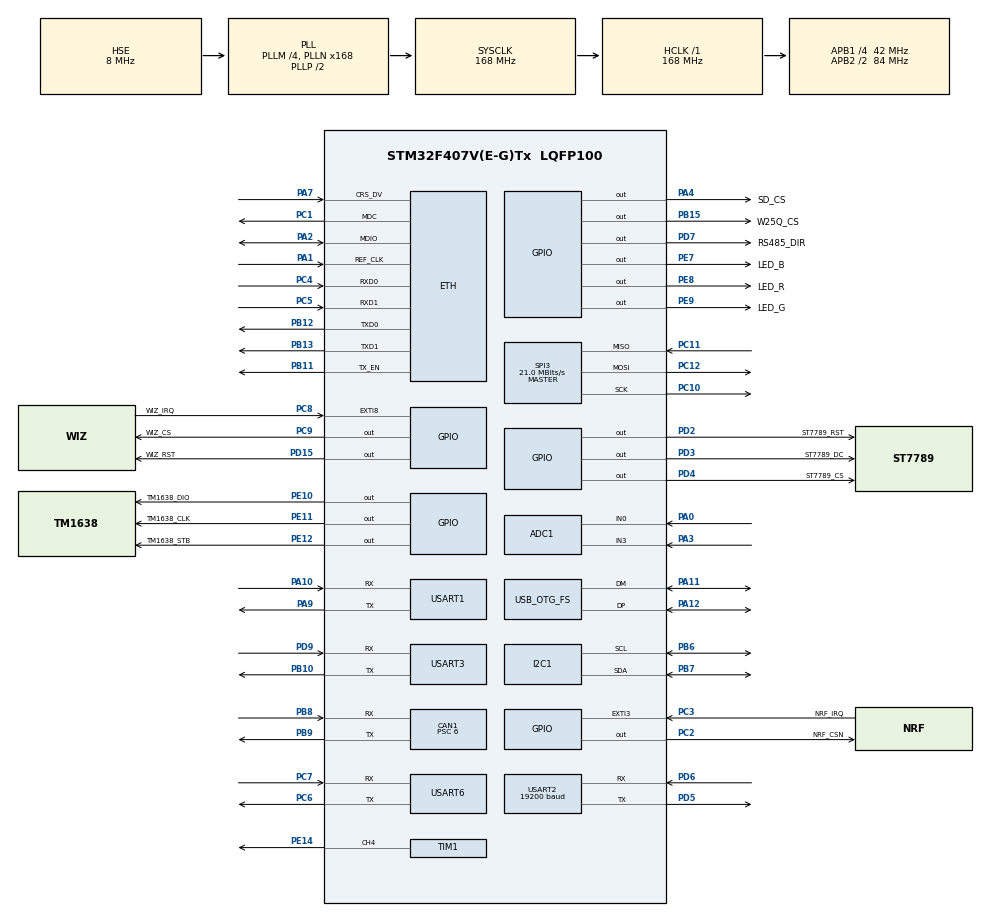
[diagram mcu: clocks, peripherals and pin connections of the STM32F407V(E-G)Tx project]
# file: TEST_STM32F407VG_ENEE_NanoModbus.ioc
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ADC1.Channel-0\#ChannelRegularConversion=ADC_CHANNEL_0
ADC1.NbrOfConversionFlag=1
ADC1.Rank-0\#ChannelRegularConversion=1
ADC1.SamplingTime-0\#ChannelRegularConversion=ADC_SAMPLETIME_3CYCLES
ADC1.master=1
CAN1.BS1=CAN_BS1_11TQ
CAN1.BS2=CAN_BS2_2TQ
CAN1.CalculateBaudRate=500000
CAN1.CalculateTimeBit=2000
CAN1.CalculateTimeQuantum=142.85714285714286
CAN1.Prescaler=6
Dma.Request0=USART1_RX
Dma.Request1=USART1_TX
Dma.Request2=SPI3_TX
Dma.Request3=TIM1_CH4/TRIG/COM
Dma.Request4=USART3_RX
Dma.Request5=USART3_TX
Dma.Request6=USART2_RX
Dma.Request7=USART2_TX
Dma.SPI3_TX.2.Direction=DMA_MEMORY_TO_PERIPH
Dma.SPI3_TX.2.FIFOMode=DMA_FIFOMODE_DISABLE
Dma.SPI3_TX.2.Instance=DMA1_Stream7
Dma.SPI3_TX.2.MemDataAlignment=DMA_MDATAALIGN_BYTE
Dma.SPI3_TX.2.MemInc=DMA_MINC_ENABLE
Dma.SPI3_TX.2.Mode=DMA_NORMAL
Dma.SPI3_TX.2.PeriphDataAlignment=DMA_PDATAALIGN_BYTE
Dma.SPI3_TX.2.PeriphInc=DMA_PINC_DISABLE
Dma.SPI3_TX.2.Priority=DMA_PRIORITY_LOW
Dma.TIM1_CH4/TRIG/COM.3.Direction=DMA_MEMORY_TO_PERIPH
Dma.TIM1_CH4/TRIG/COM.3.FIFOMode=DMA_FIFOMODE_DISABLE
Dma.TIM1_CH4/TRIG/COM.3.Instance=DMA2_Stream4
Dma.TIM1_CH4/TRIG/COM.3.MemDataAlignment=DMA_MDATAALIGN_HALFWORD
Dma.TIM1_CH4/TRIG/COM.3.MemInc=DMA_MINC_ENABLE
Dma.TIM1_CH4/TRIG/COM.3.Mode=DMA_NORMAL
Dma.TIM1_CH4/TRIG/COM.3.PeriphDataAlignment=DMA_PDATAALIGN_HALFWORD
Dma.TIM1_CH4/TRIG/COM.3.PeriphInc=DMA_PINC_DISABLE
Dma.TIM1_CH4/TRIG/COM.3.Priority=DMA_PRIORITY_MEDIUM
Dma.USART1_RX.0.Direction=DMA_PERIPH_TO_MEMORY
Dma.USART1_RX.0.FIFOMode=DMA_FIFOMODE_DISABLE
Dma.USART1_RX.0.Instance=DMA2_Stream2
Dma.USART1_RX.0.MemDataAlignment=DMA_MDATAALIGN_BYTE
Dma.USART1_RX.0.MemInc=DMA_MINC_ENABLE
Dma.USART1_RX.0.Mode=DMA_NORMAL
Dma.USART1_RX.0.PeriphDataAlignment=DMA_PDATAALIGN_BYTE
Dma.USART1_RX.0.PeriphInc=DMA_PINC_DISABLE
Dma.USART1_RX.0.Priority=DMA_PRIORITY_LOW
Dma.USART1_TX.1.Direction=DMA_MEMORY_TO_PERIPH
Dma.USART1_TX.1.FIFOMode=DMA_FIFOMODE_DISABLE
Dma.USART1_TX.1.Instance=DMA2_Stream7
Dma.USART1_TX.1.MemDataAlignment=DMA_MDATAALIGN_BYTE
Dma.USART1_TX.1.MemInc=DMA_MINC_ENABLE
Dma.USART1_TX.1.Mode=DMA_NORMAL
Dma.USART1_TX.1.PeriphDataAlignment=DMA_PDATAALIGN_BYTE
Dma.USART1_TX.1.PeriphInc=DMA_PINC_DISABLE
Dma.USART1_TX.1.Priority=DMA_PRIORITY_LOW
Dma.USART2_RX.6.Direction=DMA_PERIPH_TO_MEMORY
Dma.USART2_RX.6.FIFOMode=DMA_FIFOMODE_DISABLE
Dma.USART2_RX.6.Instance=DMA1_Stream5
Dma.USART2_RX.6.MemDataAlignment=DMA_MDATAALIGN_BYTE
Dma.USART2_RX.6.MemInc=DMA_MINC_ENABLE
Dma.USART2_RX.6.Mode=DMA_CIRCULAR
Dma.USART2_RX.6.PeriphDataAlignment=DMA_PDATAALIGN_BYTE
Dma.USART2_RX.6.PeriphInc=DMA_PINC_DISABLE
Dma.USART2_RX.6.Priority=DMA_PRIORITY_LOW
Dma.USART2_TX.7.Direction=DMA_MEMORY_TO_PERIPH
Dma.USART2_TX.7.FIFOMode=DMA_FIFOMODE_DISABLE
Dma.USART2_TX.7.Instance=DMA1_Stream6
Dma.USART2_TX.7.MemDataAlignment=DMA_MDATAALIGN_BYTE
Dma.USART2_TX.7.MemInc=DMA_MINC_ENABLE
Dma.USART2_TX.7.Mode=DMA_NORMAL
Dma.USART2_TX.7.PeriphDataAlignment=DMA_PDATAALIGN_BYTE
Dma.USART2_TX.7.PeriphInc=DMA_PINC_DISABLE
Dma.USART2_TX.7.Priority=DMA_PRIORITY_LOW
Dma.USART3_RX.4.Direction=DMA_PERIPH_TO_MEMORY
Dma.USART3_RX.4.FIFOMode=DMA_FIFOMODE_DISABLE
Dma.USART3_RX.4.Instance=DMA1_Stream1
Dma.USART3_RX.4.MemDataAlignment=DMA_MDATAALIGN_BYTE
Dma.USART3_RX.4.MemInc=DMA_MINC_ENABLE
Dma.USART3_RX.4.Mode=DMA_CIRCULAR
Dma.USART3_RX.4.PeriphDataAlignment=DMA_PDATAALIGN_BYTE
Dma.USART3_RX.4.PeriphInc=DMA_PINC_DISABLE
Dma.USART3_RX.4.Priority=DMA_PRIORITY_LOW
Dma.USART3_TX.5.Direction=DMA_MEMORY_TO_PERIPH
Dma.USART3_TX.5.FIFOMode=DMA_FIFOMODE_DISABLE
Dma.USART3_TX.5.Instance=DMA1_Stream3
Dma.USART3_TX.5.MemDataAlignment=DMA_MDATAALIGN_BYTE
Dma.USART3_TX.5.MemInc=DMA_MINC_ENABLE
Dma.USART3_TX.5.Mode=DMA_NORMAL
Dma.USART3_TX.5.PeriphDataAlignment=DMA_PDATAALIGN_BYTE
Dma.USART3_TX.5.PeriphInc=DMA_PINC_DISABLE
Dma.USART3_TX.5.Priority=DMA_PRIORITY_LOW
ETH.MediaInterface=HAL_ETH_RMII_MODE
FREERTOS.Tasks01=defaultTask,0,128,StartDefaultTask,Default,NULL,Dynamic,NULL,NULL
FREERTOS.configCHECK_FOR_STACK_OVERFLOW=2
FREERTOS.configTOTAL_HEAP_SIZE=25360
FREERTOS.configUSE_MALLOC_FAILED_HOOK=1
FREERTOS.configUSE_TIMERS=1
LWIP.BSP.number=1
LWIP.GATEWAY_ADDRESS=192.168.010.001
LWIP.IP_ADDRESS=192.168.010.010
LWIP.LWIP_DHCP=0
LWIP.NETMASK_ADDRESS=255.255.255.000
LWIP.Version=v2.1.2_Cube
LWIP0.BSP.STBoard=false
LWIP0.BSP.api=BSP_COMPONENT_DRIVER
LWIP0.BSP.component=LAN8742
LWIP0.BSP.instance=LAN8742
LWIP0.BSP.name=Driver_PHY
LWIP0.BSP.semaphore=S_LAN8742
LWIP0.BSP.solution=LAN8742
Mcu.Family=STM32F4
Mcu.Name=STM32F407V(E-G)Tx
Mcu.Package=LQFP100
NVIC.CAN1_RX0_IRQn=true\:5\:0\:false\:false\:true\:true\:true\:true\:true
NVIC.CAN1_RX1_IRQn=true\:5\:0\:false\:false\:true\:true\:true\:true\:true
NVIC.CAN1_SCE_IRQn=true\:5\:0\:false\:false\:true\:true\:true\:true\:true
NVIC.CAN1_TX_IRQn=true\:5\:0\:false\:false\:true\:true\:true\:true\:true
NVIC.DMA1_Stream1_IRQn=true\:5\:0\:false\:false\:true\:true\:false\:true\:true
NVIC.DMA1_Stream3_IRQn=true\:5\:0\:false\:false\:true\:true\:false\:true\:true
NVIC.DMA1_Stream5_IRQn=true\:5\:0\:false\:false\:true\:true\:false\:true\:true
NVIC.DMA1_Stream6_IRQn=true\:5\:0\:false\:false\:true\:true\:false\:true\:true
NVIC.DMA1_Stream7_IRQn=true\:5\:0\:false\:false\:true\:false\:false\:true\:true
NVIC.DMA2_Stream2_IRQn=true\:5\:0\:false\:false\:true\:true\:false\:true\:true
NVIC.DMA2_Stream4_IRQn=true\:5\:0\:false\:false\:true\:true\:false\:true\:true
NVIC.DMA2_Stream7_IRQn=true\:5\:0\:false\:false\:true\:true\:false\:true\:true
NVIC.ETH_IRQn=true\:5\:0\:false\:false\:true\:true\:false\:true\:true
NVIC.ETH_WKUP_IRQn=true\:5\:0\:false\:false\:true\:true\:true\:true\:true
NVIC.EXTI3_IRQn=true\:5\:0\:false\:false\:true\:true\:true\:true\:true
NVIC.OTG_FS_IRQn=true\:5\:0\:false\:false\:true\:true\:false\:true\:true
NVIC.PriorityGroup=NVIC_PRIORITYGROUP_4
NVIC.SPI3_IRQn=true\:5\:0\:false\:false\:true\:true\:true\:true\:true
NVIC.TIM7_IRQn=true\:5\:0\:false\:false\:true\:true\:true\:true\:true
NVIC.TIM8_TRG_COM_TIM14_IRQn=true\:15\:0\:false\:false\:true\:false\:false\:true\:true
NVIC.TimeBase=TIM8_TRG_COM_TIM14_IRQn
NVIC.TimeBaseIP=TIM14
NVIC.USART1_IRQn=true\:5\:0\:false\:false\:true\:true\:true\:true\:true
NVIC.USART2_IRQn=true\:5\:0\:false\:false\:true\:true\:true\:true\:true
NVIC.USART3_IRQn=true\:5\:0\:false\:false\:true\:true\:true\:true\:true
NVIC.USART6_IRQn=true\:5\:0\:false\:false\:true\:true\:true\:true\:true
PA0-WKUP.Signal=ADCx_IN0
PA1.Mode=RMII
PA1.Signal=ETH_REF_CLK
PA10.Mode=Asynchronous
PA10.Signal=USART1_RX
PA11.Mode=Device_Only
PA11.Signal=USB_OTG_FS_DM
PA12.Mode=Device_Only
PA12.Signal=USB_OTG_FS_DP
PA13.Mode=Serial_Wire
PA13.Signal=SYS_JTMS-SWDIO
PA14.Mode=Serial_Wire
PA14.Signal=SYS_JTCK-SWCLK
PA2.Mode=RMII
PA2.Signal=ETH_MDIO
PA3.Signal=ADCx_IN3
PA4.GPIO_Label=SD_CS
PA4.GPIO_PuPd=GPIO_PULLUP
PA4.GPIO_Speed=GPIO_SPEED_FREQ_MEDIUM
PA4.PinState=GPIO_PIN_SET
PA4.Signal=GPIO_Output
PA7.Mode=RMII
PA7.Signal=ETH_CRS_DV
PA9.Mode=Asynchronous
PA9.Signal=USART1_TX
PB10.Mode=Asynchronous
PB10.Signal=USART3_TX
PB11.Mode=RMII
PB11.Signal=ETH_TX_EN
PB12.Mode=RMII
PB12.Signal=ETH_TXD0
PB13.Mode=RMII
PB13.Signal=ETH_TXD1
PB15.GPIO_Label=W25Q_CS
PB15.GPIO_PuPd=GPIO_PULLUP
PB15.GPIO_Speed=GPIO_SPEED_FREQ_MEDIUM
PB15.PinState=GPIO_PIN_SET
PB15.Signal=GPIO_Output
PB6.GPIO_Pu=GPIO_PULLUP
PB6.Mode=I2C
PB6.Signal=I2C1_SCL
PB7.GPIO_Pu=GPIO_PULLUP
PB7.Mode=I2C
PB7.Signal=I2C1_SDA
PB8.Mode=CAN_Activate
PB8.Signal=CAN1_RX
PB9.Mode=CAN_Activate
PB9.Signal=CAN1_TX
PC1.Mode=RMII
PC1.Signal=ETH_MDC
PC10.Mode=Full_Duplex_Master
PC10.Signal=SPI3_SCK
PC11.Mode=Full_Duplex_Master
PC11.Signal=SPI3_MISO
PC12.Mode=Full_Duplex_Master
PC12.Signal=SPI3_MOSI
PC14-OSC32_IN.Mode=LSE-External-Oscillator
PC14-OSC32_IN.Signal=RCC_OSC32_IN
PC15-OSC32_OUT.Mode=LSE-External-Oscillator
PC15-OSC32_OUT.Signal=RCC_OSC32_OUT
PC2.GPIO_Label=NRF_CSN
PC2.PinState=GPIO_PIN_SET
PC2.Signal=GPIO_Output
PC3.GPIO_Label=NRF_IRQ
PC3.GPIO_PuPd=GPIO_PULLUP
PC3.Signal=GPXTI3
PC4.Mode=RMII
PC4.Signal=ETH_RXD0
PC5.Mode=RMII
PC5.Signal=ETH_RXD1
PC6.Mode=Asynchronous
PC6.Signal=USART6_TX
PC7.Mode=Asynchronous
PC7.Signal=USART6_RX
PC8.GPIO_Label=WIZ_IRQ
PC8.Signal=GPXTI8
PC9.GPIO_Label=WIZ_CS
PC9.Signal=GPIO_Output
PD15.GPIO_Label=WIZ_RST
PD15.Signal=GPIO_Output
PD2.GPIO_Label=ST7789_RST
PD2.Signal=GPIO_Output
PD3.GPIO_Label=ST7789_DC
PD3.Signal=GPIO_Output
PD4.GPIO_Label=ST7789_CS
PD4.GPIO_PuPd=GPIO_PULLUP
PD4.GPIO_Speed=GPIO_SPEED_FREQ_MEDIUM
PD4.PinState=GPIO_PIN_SET
PD4.Signal=GPIO_Output
PD5.Mode=Asynchronous
PD5.Signal=USART2_TX
PD6.Mode=Asynchronous
PD6.Signal=USART2_RX
PD7.GPIO_Label=RS485_DIR
PD7.Signal=GPIO_Output
PD9.Mode=Asynchronous
PD9.Signal=USART3_RX
PE10.GPIO_Label=TM1638_DIO
PE10.Signal=GPIO_Output
PE11.GPIO_Label=TM1638_CLK
PE11.Signal=GPIO_Output
PE12.GPIO_Label=TM1638_STB
PE12.Signal=GPIO_Output
PE14.Signal=S_TIM1_CH4
PE7.GPIO_Label=LED_B
PE7.GPIO_PuPd=GPIO_PULLUP
PE7.Signal=GPIO_Output
PE8.GPIO_Label=LED_R
PE8.GPIO_PuPd=GPIO_PULLUP
PE8.Signal=GPIO_Output
PE9.GPIO_Label=LED_G
PE9.GPIO_PuPd=GPIO_PULLUP
PE9.Signal=GPIO_Output
PH0-OSC_IN.Mode=HSE-External-Oscillator
PH0-OSC_IN.Signal=RCC_OSC_IN
PH1-OSC_OUT.Mode=HSE-External-Oscillator
PH1-OSC_OUT.Signal=RCC_OSC_OUT
ProjectManager.HeapSize=0x800
ProjectManager.StackSize=0x800
ProjectManager.TargetToolchain=MDK-ARM V5
RCC.48MHZClocksFreq_Value=48000000
RCC.AHBFreq_Value=168000000
RCC.APB1CLKDivider=RCC_HCLK_DIV4
RCC.APB1Freq_Value=42000000
RCC.APB1TimFreq_Value=84000000
RCC.APB2CLKDivider=RCC_HCLK_DIV2
RCC.APB2Freq_Value=84000000
RCC.APB2TimFreq_Value=168000000
RCC.CortexFreq_Value=168000000
RCC.HCLKFreq_Value=168000000
RCC.HSE_VALUE=8000000
RCC.HSI_VALUE=16000000
RCC.PLLM=4
RCC.PLLN=168
RCC.PLLQ=7
RCC.RCC_RTC_Clock_Source=RCC_RTCCLKSOURCE_LSE
RCC.RCC_RTC_Clock_SourceVirtual=RCC_RTCCLKSOURCE_LSE
RCC.SYSCLKFreq_VALUE=168000000
RCC.SYSCLKSource=RCC_SYSCLKSOURCE_PLLCLK
RCC.VCOOutputFreq_Value=336000000
SH.ADCx_IN0.0=ADC1_IN0,IN0
SH.ADCx_IN3.0=ADC1_IN3,IN3
SH.S_TIM1_CH4.0=TIM1_CH4,PWM Generation4 CH4
SPI3.BaudRatePrescaler=SPI_BAUDRATEPRESCALER_2
SPI3.CLKPolarity=SPI_POLARITY_LOW
SPI3.CalculateBaudRate=21.0 MBits/s
SPI3.Direction=SPI_DIRECTION_2LINES
SPI3.Mode=SPI_MODE_MASTER
SPI3.VirtualType=VM_MASTER
TIM1.Channel-PWM\ Generation4\ CH4=TIM_CHANNEL_4
TIM1.Period=209
USART1.VirtualMode=VM_ASYNC
USART2.BaudRate=19200
USART2.VirtualMode=VM_ASYNC
USART3.VirtualMode=VM_ASYNC
USART6.VirtualMode=VM_ASYNC
USB_DEVICE.CLASS_NAME_FS=CDC
USB_DEVICE.VirtualMode-CDC_FS=Cdc
USB_DEVICE.VirtualModeFS=Cdc_FS
USB_OTG_FS.VirtualMode=Device_Only
VP_FATFS_VS_Generic.Mode=User_defined
VP_FREERTOS_VS_CMSIS_V1.Mode=CMSIS_V1
VP_LWIP_VS_Enabled.Mode=Enabled
VP_RTC_VS_RTC_Activate.Mode=RTC_Enabled
VP_RTC_VS_RTC_Calendar.Mode=RTC_Calendar
VP_SYS_VS_tim14.Mode=TIM14
VP_TIM7_VS_ClockSourceINT.Mode=Enable_Timer
VP_USB_DEVICE_VS_USB_DEVICE_CDC_FS.Mode=CDC_FS
board=custom

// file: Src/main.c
/* USER CODE BEGIN Header */
/**
  ******************************************************************************
  * @file           : main.c
  * @brief          : Main program body
  ******************************************************************************
  * @attention
  *
  * Copyright (c) 2026 STMicroelectronics.
  * All rights reserved.
  *
  * This software is licensed under terms that can be found in the LICENSE file
  * in the root directory of this software component.
  * If no LICENSE file comes with this software, it is provided AS-IS.
  *
  ******************************************************************************
  */
/* USER CODE END Header */
#include "main.h"
#include "cmsis_os.h"
#include "adc.h"
#include "can.h"
#include "dma.h"
#include "fatfs.h"
#include "i2c.h"
#include "lwip.h"
#include "rtc.h"
#include "spi.h"
#include "tim.h"
#include "usart.h"
#include "usb_device.h"
#include "gpio.h"

/* USER CODE BEGIN Includes */
#include "trcRecorder.h"
/* USER CODE END Includes */

void SystemClock_Config(void);
void MX_FREERTOS_Init(void);

int main(void)
{

  /* MCU Configuration--------------------------------------------------------*/

  /* Reset of all peripherals, Initializes the Flash interface and the Systick. */
  HAL_Init();

  /* Configure the system clock */
  SystemClock_Config();

  /* Initialize all configured peripherals */
  MX_GPIO_Init();
  MX_DMA_Init();
  MX_CAN1_Init();
  MX_I2C1_Init();
  MX_RTC_Init();
  MX_SPI3_Init();
  MX_USART3_UART_Init();
  MX_FATFS_Init();
  MX_USART1_UART_Init();
  MX_ADC1_Init();
  MX_USART2_UART_Init();
  MX_TIM1_Init();
  MX_USART6_UART_Init();
  MX_TIM7_Init();
  /* USER CODE BEGIN 2 */
  vTraceEnable(TRC_START);
  /* USER CODE END 2 */

  /* Call init function for freertos objects (in cmsis_os2.c) */
  MX_FREERTOS_Init();

  /* Start scheduler */
  osKernelStart();

  /* We should never get here as control is now taken by the scheduler */

  /* Infinite loop */
  while (1)
  {

  }
}

void SystemClock_Config(void)
{
  RCC_OscInitTypeDef RCC_OscInitStruct = {0};
  RCC_ClkInitTypeDef RCC_ClkInitStruct = {0};

  /** Configure the main internal regulator output voltage
  */
  __HAL_RCC_PWR_CLK_ENABLE();
  __HAL_PWR_VOLTAGESCALING_CONFIG(PWR_REGULATOR_VOLTAGE_SCALE1);

  /** Initializes the RCC Oscillators according to the specified parameters
  * in the RCC_OscInitTypeDef structure.
  */
  RCC_OscInitStruct.OscillatorType = RCC_OSCILLATORTYPE_HSE|RCC_OSCILLATORTYPE_LSE;
  RCC_OscInitStruct.HSEState = RCC_HSE_ON;
  RCC_OscInitStruct.LSEState = RCC_LSE_ON;
  RCC_OscInitStruct.PLL.PLLState = RCC_PLL_ON;
  RCC_OscInitStruct.PLL.PLLSource = RCC_PLLSOURCE_HSE;
  RCC_OscInitStruct.PLL.PLLM = 4;
  RCC_OscInitStruct.PLL.PLLN = 168;
  RCC_OscInitStruct.PLL.PLLP = RCC_PLLP_DIV2;
  RCC_OscInitStruct.PLL.PLLQ = 7;
  if (HAL_RCC_OscConfig(&RCC_OscInitStruct) != HAL_OK)
  {
    Error_Handler();
  }

  /** Initializes the CPU, AHB and APB buses clocks
  */
  RCC_ClkInitStruct.ClockType = RCC_CLOCKTYPE_HCLK|RCC_CLOCKTYPE_SYSCLK
                              |RCC_CLOCKTYPE_PCLK1|RCC_CLOCKTYPE_PCLK2;
  RCC_ClkInitStruct.SYSCLKSource = RCC_SYSCLKSOURCE_PLLCLK;
  RCC_ClkInitStruct.AHBCLKDivider = RCC_SYSCLK_DIV1;
  RCC_ClkInitStruct.APB1CLKDivider = RCC_HCLK_DIV4;
  RCC_ClkInitStruct.APB2CLKDivider = RCC_HCLK_DIV2;

  if (HAL_RCC_ClockConfig(&RCC_ClkInitStruct, FLASH_LATENCY_5) != HAL_OK)
  {
    Error_Handler();
  }
}

void HAL_TIM_PeriodElapsedCallback(TIM_HandleTypeDef *htim)
{
  if (htim->Instance == TIM14)
  {
    HAL_IncTick();
  }
}

void Error_Handler(void)
{
  __disable_irq();
  while (1)
  {
  }
}
